# nrf52840 register map
Vendor: Nordic Semiconductor; Series: nrf52; File version: 1
CPU: CM4 r0p1, little endian, MPU, FPU, 3 interrupt priority bits
Registers are 32-bit, read-write, reset 0x0 unless marked. A register's access mark holds for its fields unless they carry their own. Offsets are from the block's base; [hi:lo] are bit positions; lines under a group give offsets from that group; {n}, {i} and the like mark numbered series.

## PPI — Programmable Peripheral Interconnect
Base 0x4001F000
{0x0+8i} TASKS_CHG[{i}] (i=0..5) group — Channel group tasks
  0x00 EN wo — Description cluster: Enable channel group n
    [0] EN — Enable channel group n
      1=Trigger task
  0x04 DIS wo — Description cluster: Disable channel group n
    [0] DIS — Disable channel group n
      1=Trigger task
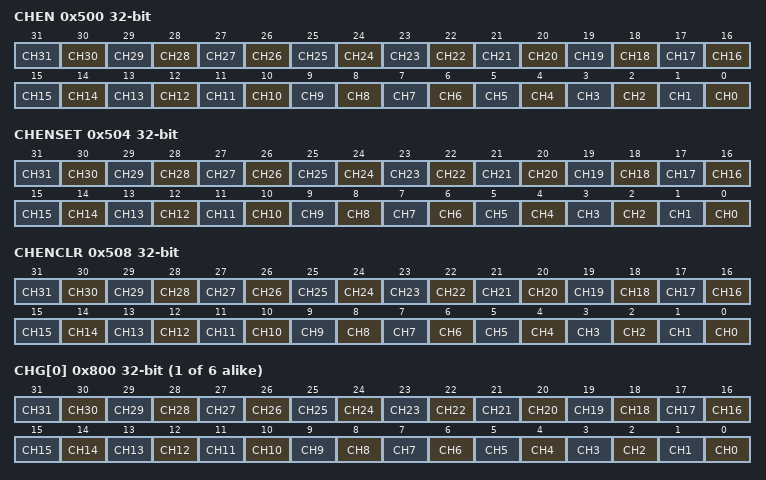
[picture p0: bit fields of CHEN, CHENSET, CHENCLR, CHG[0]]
0x500 CHEN — Channel enable register
  [all] fields
    0=Disabled (Disable channel); 1=Enabled (Enable channel)
  [n] CH{n} (n=0..31) — Enable or disable channel {n}
0x504 CHENSET write-1-sets — Channel enable set register
  [all] fields
    on read: 0=Disabled (Read: channel disabled); 1=Enabled (Read: channel enabled) | on write: 1=Set (Write: Enable channel)
  [n] CH{n} (n=0..31) — Channel {n} enable set register. Writing '0' has no effect
0x508 CHENCLR write-1-clears — Channel enable clear register
  [all] fields
    on read: 0=Disabled (Read: channel disabled); 1=Enabled (Read: channel enabled) | on write: 1=Clear (Write: disable channel)
  [n] CH{n} (n=0..31) — Channel {n} enable clear register. Writing '0' has no effect
{0x510+8i} CH[{i}] (i=0..19) group — PPI Channel
  0x00 EEP — Description cluster: Channel n event end-point
    [31:0] EEP — Pointer to event register. Accepts only addresses to registers from the Event group.
  0x04 TEP — Description cluster: Channel n task end-point
    [31:0] TEP — Pointer to task register. Accepts only addresses to registers from the Task group.
{0x800+4i} CHG[{i}] (i=0..5) — Description collection: Channel group n
  [all] fields
    0=Excluded; 1=Included
  [n] CH{n} (n=0..31) — Include or exclude channel {n}
{0x910+4i} FORK[{i}] (i=0..31) group
  0x00 TEP — Description cluster: Channel n task end-point
    [31:0] TEP — Pointer to task register

## CC_HOST_RGF — CRYPTOCELL HOST_RGF interface
Base 0x5002A000
0x1A38 HOST_CRYPTOKEY_SEL — AES hardware key select
  [1:0] HOST_CRYPTOKEY_SEL — Select the source of the HW key that is used by the AES engine
    0=K_DR (Use device root key K_DR from CRYPTOCELL AO power domain); 1=K_PRTL (Use hard-coded RTL key K_PRTL); 2=Session (Use provided session key)
0x1A4C HOST_IOT_KPRTL_LOCK — This write-once register is the K_PRTL lock register. When this register is set, K_PRTL can not be used and a zeroed key will be used instead. The value of this register is saved in the CRYPTOCELL AO power domain.
  [0] HOST_IOT_KPRTL_LOCK — This register is the K_PRTL lock register. When this register is set, K_PRTL can not be used and a zeroed key will be used instead. The value of this register is saved in the CRYPTOCELL AO power domain.
    0=Disabled (K_PRTL can be selected for use from register HOST_CRYPTOKEY_SEL); 1=Enabled (K_PRTL has been locked until next power-on reset (POR). If K_PRTL is selected anyway, a zeroed key will be used instead.)
0x1A50 HOST_IOT_KDR0 — This register holds bits 31:0 of K_DR. The value of this register is saved in the CRYPTOCELL AO power domain. Reading from this address returns the K_DR valid status indicating if K_DR is successfully retained.
  [31:0] HOST_IOT_KDR0 — Write: K_DR bits 31:0 Read: 0x00000000 when 128-bit K_DR key value is not yet retained in the CRYPTOCELL AO power domain Read: 0x00000001 when 128-bit K_DR key value is successfully retained in the CRYPTOCELL AO power domain
{0x1A50+4i} HOST_IOT_KDR{i} wo (i=1..3) — This register holds bits {32i+31}:{32i} of K_DR. The value of this register is saved in the CRYPTOCELL AO power domain.
  [31:0] HOST_IOT_KDR{i} — K_DR bits {32i+31}:{32i}
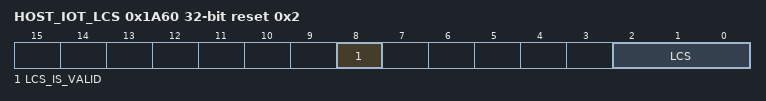
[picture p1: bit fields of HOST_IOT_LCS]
0x1A60 HOST_IOT_LCS reset 0x2 — Controls lifecycle state (LCS) for CRYPTOCELL subsystem
  [8] LCS_IS_VALID — This field is read-only and indicates if CRYPTOCELL LCS has been successfully configured since last reset
    0=Invalid (A valid LCS is not yet retained in the CRYPTOCELL AO power domain); 1=Valid (A valid LCS is successfully retained in the CRYPTOCELL AO power domain)
  [2:0] LCS — Lifecycle state value. This field is write-once per reset.
    0=Debug (CC310 operates in debug mode); 2=Secure (CC310 operates in secure mode)

## CRYPTOCELL — ARM TrustZone CryptoCell register interface
Base 0x5002A000; alternate view of CC_HOST_RGF
0x500 ENABLE — Enable CRYPTOCELL subsystem
  [0] ENABLE — Enable or disable the CRYPTOCELL subsystem
    0=Disabled (CRYPTOCELL subsystem disabled); 1=Enabled (CRYPTOCELL subsystem enabled)
